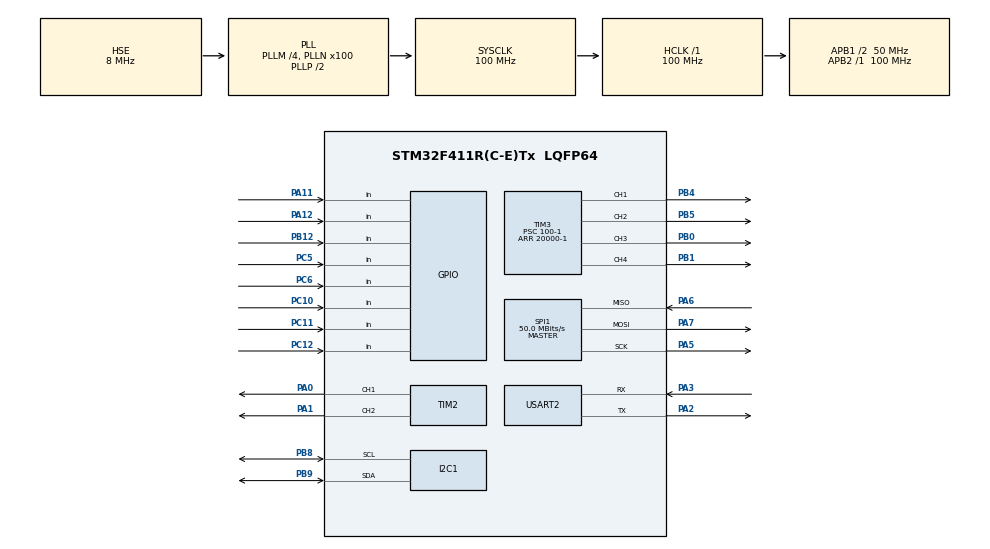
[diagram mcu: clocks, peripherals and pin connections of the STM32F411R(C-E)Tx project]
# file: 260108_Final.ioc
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FREERTOS.Tasks01=defaultTask,0,128,StartDefaultTask,Default,NULL,Dynamic,NULL,NULL;ListenerTask,0,128,Listener,Default,NULL,Dynamic,NULL,NULL;ControllerTask,0,128,Controller,Default,NULL,Dynamic,NULL,NULL;PresenterTask,0,128,Presenter,Default,NULL,Dynamic,NULL,NULL
FREERTOS.configUSE_NEWLIB_REENTRANT=1
Mcu.Family=STM32F4
Mcu.Name=STM32F411R(C-E)Tx
Mcu.Package=LQFP64
NVIC.PriorityGroup=NVIC_PRIORITYGROUP_4
NVIC.SPI1_IRQn=true\:5\:0\:false\:false\:true\:true\:true\:true\:true
NVIC.TIM1_TRG_COM_TIM11_IRQn=true\:15\:0\:false\:false\:true\:false\:false\:true\:true
NVIC.TIM1_UP_TIM10_IRQn=true\:5\:0\:false\:false\:true\:true\:true\:true\:true
NVIC.TIM3_IRQn=true\:5\:0\:false\:false\:true\:true\:true\:true\:true
NVIC.TimeBase=TIM1_TRG_COM_TIM11_IRQn
NVIC.TimeBaseIP=TIM11
PA0-WKUP.Signal=S_TIM2_CH1_ETR
PA1.Signal=S_TIM2_CH2
PA11.Signal=GPIO_Input
PA12.Signal=GPIO_Input
PA13.Mode=Serial_Wire
PA13.Signal=SYS_JTMS-SWDIO
PA14.Mode=Serial_Wire
PA14.Signal=SYS_JTCK-SWCLK
PA2.Mode=Asynchronous
PA2.Signal=USART2_TX
PA3.Mode=Asynchronous
PA3.Signal=USART2_RX
PA5.Mode=Full_Duplex_Master
PA5.Signal=SPI1_SCK
PA6.Mode=Full_Duplex_Master
PA6.Signal=SPI1_MISO
PA7.Mode=Full_Duplex_Master
PA7.Signal=SPI1_MOSI
PB0.Signal=S_TIM3_CH3
PB1.Signal=S_TIM3_CH4
PB12.Signal=GPIO_Input
PB4.Signal=S_TIM3_CH1
PB5.Signal=S_TIM3_CH2
PB8.Mode=I2C
PB8.Signal=I2C1_SCL
PB9.Mode=I2C
PB9.Signal=I2C1_SDA
PC10.Signal=GPIO_Input
PC11.Signal=GPIO_Input
PC12.Signal=GPIO_Input
PC5.Signal=GPIO_Input
PC6.Signal=GPIO_Input
PH0\ -\ OSC_IN.Mode=HSE-External-Oscillator
PH0\ -\ OSC_IN.Signal=RCC_OSC_IN
PH1\ -\ OSC_OUT.Mode=HSE-External-Oscillator
PH1\ -\ OSC_OUT.Signal=RCC_OSC_OUT
ProjectManager.HeapSize=0x200
ProjectManager.StackSize=0x400
ProjectManager.TargetToolchain=STM32CubeIDE
RCC.48MHZClocksFreq_Value=50000000
RCC.AHBFreq_Value=100000000
RCC.APB1CLKDivider=RCC_HCLK_DIV2
RCC.APB1Freq_Value=50000000
RCC.APB1TimFreq_Value=100000000
RCC.APB2Freq_Value=100000000
RCC.APB2TimFreq_Value=100000000
RCC.CortexFreq_Value=100000000
RCC.HCLKFreq_Value=100000000
RCC.HSE_VALUE=8000000
RCC.HSI_VALUE=16000000
RCC.LSE_VALUE=32768
RCC.PLLM=4
RCC.PLLN=100
RCC.PLLSourceVirtual=RCC_PLLSOURCE_HSE
RCC.SYSCLKFreq_VALUE=100000000
RCC.SYSCLKSource=RCC_SYSCLKSOURCE_PLLCLK
RCC.VCOOutputFreq_Value=200000000
SH.S_TIM2_CH1_ETR.0=TIM2_CH1,PWM Generation1 CH1
SH.S_TIM2_CH2.0=TIM2_CH2,PWM Generation2 CH2
SH.S_TIM3_CH1.0=TIM3_CH1,PWM Generation1 CH1
SH.S_TIM3_CH2.0=TIM3_CH2,PWM Generation2 CH2
SH.S_TIM3_CH3.0=TIM3_CH3,PWM Generation3 CH3
SH.S_TIM3_CH4.0=TIM3_CH4,PWM Generation4 CH4
SPI1.CalculateBaudRate=50.0 MBits/s
SPI1.Direction=SPI_DIRECTION_2LINES
SPI1.Mode=SPI_MODE_MASTER
SPI1.VirtualType=VM_MASTER
TIM1.Period=1000-1
TIM1.Prescaler=100-1
TIM2.Channel-PWM\ Generation1\ CH1=TIM_CHANNEL_1
TIM2.Channel-PWM\ Generation2\ CH2=TIM_CHANNEL_2
TIM3.Channel-PWM\ Generation1\ CH1=TIM_CHANNEL_1
TIM3.Channel-PWM\ Generation2\ CH2=TIM_CHANNEL_2
TIM3.Channel-PWM\ Generation3\ CH3=TIM_CHANNEL_3
TIM3.Channel-PWM\ Generation4\ CH4=TIM_CHANNEL_4
TIM3.Period=20000-1
TIM3.Prescaler=100-1
USART2.VirtualMode=VM_ASYNC
VP_FREERTOS_VS_CMSIS_V1.Mode=CMSIS_V1
VP_SYS_VS_tim11.Mode=TIM11
VP_TIM1_VS_ClockSourceINT.Mode=Internal
VP_TIM2_VS_ClockSourceINT.Mode=Internal
VP_TIM3_VS_ClockSourceINT.Mode=Internal
board=custom

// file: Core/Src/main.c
/* USER CODE BEGIN Header */
/**
 ******************************************************************************
 * @file           : main.c
 * @brief          : Main program body
 ******************************************************************************
 * @attention
 *
 * Copyright (c) 2026 STMicroelectronics.
 * All rights reserved.
 *
 * This software is licensed under terms that can be found in the LICENSE file
 * in the root directory of this software component.
 * If no LICENSE file comes with this software, it is provided AS-IS.
 *
 ******************************************************************************
 */
/* USER CODE END Header */
#include "main.h"
#include "cmsis_os.h"
#include "i2c.h"
#include "spi.h"
#include "tim.h"
#include "usart.h"
#include "gpio.h"

/* USER CODE BEGIN Includes */
#include "../ap/Listener/Listener_Tracking.h"
/* USER CODE END Includes */

/* USER CODE BEGIN PV */
extern I2C_HandleTypeDef hi2c1;
extern SPI_HandleTypeDef hspi1;
extern UART_HandleTypeDef huart2;
/* USER CODE END PV */

void SystemClock_Config(void);
void MX_FREERTOS_Init(void);

int main(void)
{

  /* MCU Configuration--------------------------------------------------------*/

  /* Reset of all peripherals, Initializes the Flash interface and the Systick. */
  HAL_Init();

  /* Configure the system clock */
  SystemClock_Config();

  /* Initialize all configured peripherals */
  MX_GPIO_Init();
  MX_I2C1_Init();
  MX_TIM1_Init();
  MX_USART2_UART_Init();
  MX_TIM2_Init();
  MX_SPI1_Init();
  MX_TIM3_Init();
  /* USER CODE BEGIN 2 */

  // UART 테스트 메시지 (시스템 시작 확인)
  printf("========================================\r\n");
  printf("  STM32 System Initialized\r\n");
  printf("  UART2 Working - Baud: 115200\r\n");
  printf("========================================\r\n");

  /* USER CODE END 2 */

  /* Call init function for freertos objects (in cmsis_os2.c) */
  MX_FREERTOS_Init();

  /* Start scheduler */
  osKernelStart();

  /* We should never get here as control is now taken by the scheduler */

  /* Infinite loop */
	while (1) {

	}
}

void SystemClock_Config(void)
{
  RCC_OscInitTypeDef RCC_OscInitStruct = {0};
  RCC_ClkInitTypeDef RCC_ClkInitStruct = {0};

  /** Configure the main internal regulator output voltage
  */
  __HAL_RCC_PWR_CLK_ENABLE();
  __HAL_PWR_VOLTAGESCALING_CONFIG(PWR_REGULATOR_VOLTAGE_SCALE1);

  /** Initializes the RCC Oscillators according to the specified parameters
  * in the RCC_OscInitTypeDef structure.
  */
  RCC_OscInitStruct.OscillatorType = RCC_OSCILLATORTYPE_HSE;
  RCC_OscInitStruct.HSEState = RCC_HSE_ON;
  RCC_OscInitStruct.PLL.PLLState = RCC_PLL_ON;
  RCC_OscInitStruct.PLL.PLLSource = RCC_PLLSOURCE_HSE;
  RCC_OscInitStruct.PLL.PLLM = 4;
  RCC_OscInitStruct.PLL.PLLN = 100;
  RCC_OscInitStruct.PLL.PLLP = RCC_PLLP_DIV2;
  RCC_OscInitStruct.PLL.PLLQ = 4;
  if (HAL_RCC_OscConfig(&RCC_OscInitStruct) != HAL_OK)
  {
    Error_Handler();
  }

  /** Initializes the CPU, AHB and APB buses clocks
  */
  RCC_ClkInitStruct.ClockType = RCC_CLOCKTYPE_HCLK|RCC_CLOCKTYPE_SYSCLK
                              |RCC_CLOCKTYPE_PCLK1|RCC_CLOCKTYPE_PCLK2;
  RCC_ClkInitStruct.SYSCLKSource = RCC_SYSCLKSOURCE_PLLCLK;
  RCC_ClkInitStruct.AHBCLKDivider = RCC_SYSCLK_DIV1;
  RCC_ClkInitStruct.APB1CLKDivider = RCC_HCLK_DIV2;
  RCC_ClkInitStruct.APB2CLKDivider = RCC_HCLK_DIV1;

  if (HAL_RCC_ClockConfig(&RCC_ClkInitStruct, FLASH_LATENCY_3) != HAL_OK)
  {
    Error_Handler();
  }
}

void HAL_TIM_PeriodElapsedCallback(TIM_HandleTypeDef *htim)
{
  if (htim->Instance == TIM11)
  {
    HAL_IncTick();
  }
  /* USER CODE BEGIN Callback 1 */
	if (htim->Instance == TIM3) {
		Listener_Tracking_TIM_ISR();
	}
  /* USER CODE END Callback 1 */
}

void Error_Handler(void)
{
	__disable_irq();
	while (1) {
	}
}
